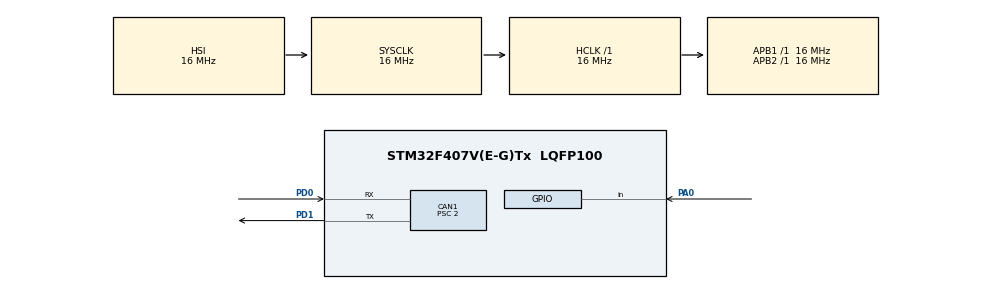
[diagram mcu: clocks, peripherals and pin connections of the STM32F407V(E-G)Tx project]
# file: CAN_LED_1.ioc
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CAN1.BS1=CAN_BS1_13TQ
CAN1.BS2=CAN_BS2_2TQ
CAN1.CalculateBaudRate=500000
CAN1.CalculateTimeBit=2000
CAN1.CalculateTimeQuantum=125.0
CAN1.NART=ENABLE
CAN1.Prescaler=2
Mcu.Family=STM32F4
Mcu.Name=STM32F407V(E-G)Tx
Mcu.Package=LQFP100
NVIC.PriorityGroup=NVIC_PRIORITYGROUP_4
PA0-WKUP.Signal=GPIO_Input
PD0.Mode=CAN_Activate
PD0.Signal=CAN1_RX
PD1.Mode=CAN_Activate
PD1.Signal=CAN1_TX
ProjectManager.HeapSize=0x200
ProjectManager.StackSize=0x400
ProjectManager.TargetToolchain=STM32CubeIDE
RCC.AHBFreq_Value=16000000
RCC.APB1Freq_Value=16000000
RCC.APB2Freq_Value=16000000
RCC.CortexFreq_Value=16000000
RCC.HSE_VALUE=25000000
RCC.HSI_VALUE=16000000
RCC.LSE_VALUE=32768
RCC.SYSCLKFreq_VALUE=16000000
RCC.VCOOutputFreq_Value=192000000
board=custom

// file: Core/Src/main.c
/* USER CODE BEGIN Header */
/**
  ******************************************************************************
  * @file           : main.c
  * @brief          : Main program body
  ******************************************************************************
  * @attention
  *
  * Copyright (c) 2026 STMicroelectronics.
  * All rights reserved.
  *
  * This software is licensed under terms that can be found in the LICENSE file
  * in the root directory of this software component.
  * If no LICENSE file comes with this software, it is provided AS-IS.
  *
  ******************************************************************************
  */
/* USER CODE END Header */
#include "main.h"

CAN_HandleTypeDef hcan1;

/* USER CODE BEGIN PV */
CAN_TxHeaderTypeDef TxHeader;
uint8_t TxData[1];
uint32_t TxMailbox;

uint8_t buttonLastState = 0;
uint32_t lastDebounceTime = 0;
#define DEBOUNCE_MS 50
/* USER CODE END PV */

void SystemClock_Config(void);
static void MX_GPIO_Init(void);
static void MX_CAN1_Init(void);

int main(void)
{

  /* MCU Configuration--------------------------------------------------------*/

  /* Reset of all peripherals, Initializes the Flash interface and the Systick. */
  HAL_Init();

  /* Configure the system clock */
  SystemClock_Config();

  /* Initialize all configured peripherals */
  MX_GPIO_Init();
  MX_CAN1_Init();
  /* USER CODE BEGIN 2 */
  CAN_FilterTypeDef canFilter;
  canFilter.FilterBank = 0;
  canFilter.FilterMode = CAN_FILTERMODE_IDMASK;
  canFilter.FilterScale = CAN_FILTERSCALE_32BIT;
  canFilter.FilterIdHigh = 0x0000;
  canFilter.FilterIdLow = 0x0000;
  canFilter.FilterMaskIdHigh = 0x0000;
  canFilter.FilterMaskIdLow = 0x0000;
  canFilter.FilterFIFOAssignment = CAN_FILTER_FIFO0;
  canFilter.FilterActivation = ENABLE;
  canFilter.SlaveStartFilterBank = 14;

  if (HAL_CAN_ConfigFilter(&hcan1, &canFilter) != HAL_OK)
  {
    Error_Handler();
  }

  if (HAL_CAN_Start(&hcan1) != HAL_OK)
  {
    Error_Handler();
  }

  TxHeader.StdId = 0x100;
  TxHeader.ExtId = 0;
  TxHeader.IDE = CAN_ID_STD;
  TxHeader.RTR = CAN_RTR_DATA;
  TxHeader.DLC = 1;
  TxHeader.TransmitGlobalTime = DISABLE;
  /* USER CODE END 2 */

  /* Infinite loop */
  /* USER CODE BEGIN WHILE */
  while (1)
  {
	  uint8_t buttonState = HAL_GPIO_ReadPin(GPIOA, GPIO_PIN_0);

	  // Rising-edge detect with simple software debounce
	  if (buttonState == GPIO_PIN_SET && buttonLastState == GPIO_PIN_RESET
	      && (HAL_GetTick() - lastDebounceTime) > DEBOUNCE_MS)
	  {
	    TxData[0] = 0xAA;

	    if (HAL_CAN_AddTxMessage(&hcan1, &TxHeader, TxData, &TxMailbox) != HAL_OK)
	    {
	      Error_Handler();
	    }

	    lastDebounceTime = HAL_GetTick();
	  }

	  buttonLastState = buttonState;
    /* USER CODE END WHILE */

  }
}

void SystemClock_Config(void)
{
  RCC_OscInitTypeDef RCC_OscInitStruct = {0};
  RCC_ClkInitTypeDef RCC_ClkInitStruct = {0};

  /** Configure the main internal regulator output voltage
  */
  __HAL_RCC_PWR_CLK_ENABLE();
  __HAL_PWR_VOLTAGESCALING_CONFIG(PWR_REGULATOR_VOLTAGE_SCALE1);

  /** Initializes the RCC Oscillators according to the specified parameters
  * in the RCC_OscInitTypeDef structure.
  */
  RCC_OscInitStruct.OscillatorType = RCC_OSCILLATORTYPE_HSI;
  RCC_OscInitStruct.HSIState = RCC_HSI_ON;
  RCC_OscInitStruct.HSICalibrationValue = RCC_HSICALIBRATION_DEFAULT;
  RCC_OscInitStruct.PLL.PLLState = RCC_PLL_NONE;
  if (HAL_RCC_OscConfig(&RCC_OscInitStruct) != HAL_OK)
  {
    Error_Handler();
  }

  /** Initializes the CPU, AHB and APB buses clocks
  */
  RCC_ClkInitStruct.ClockType = RCC_CLOCKTYPE_HCLK|RCC_CLOCKTYPE_SYSCLK
                              |RCC_CLOCKTYPE_PCLK1|RCC_CLOCKTYPE_PCLK2;
  RCC_ClkInitStruct.SYSCLKSource = RCC_SYSCLKSOURCE_HSI;
  RCC_ClkInitStruct.AHBCLKDivider = RCC_SYSCLK_DIV1;
  RCC_ClkInitStruct.APB1CLKDivider = RCC_HCLK_DIV1;
  RCC_ClkInitStruct.APB2CLKDivider = RCC_HCLK_DIV1;

  if (HAL_RCC_ClockConfig(&RCC_ClkInitStruct, FLASH_LATENCY_0) != HAL_OK)
  {
    Error_Handler();
  }
}

static void MX_CAN1_Init(void)
{

  hcan1.Instance = CAN1;
  hcan1.Init.Prescaler = 2;
  hcan1.Init.Mode = CAN_MODE_NORMAL;
  hcan1.Init.SyncJumpWidth = CAN_SJW_1TQ;
  hcan1.Init.TimeSeg1 = CAN_BS1_13TQ;
  hcan1.Init.TimeSeg2 = CAN_BS2_2TQ;
  hcan1.Init.TimeTriggeredMode = DISABLE;
  hcan1.Init.AutoBusOff = DISABLE;
  hcan1.Init.AutoWakeUp = DISABLE;
  hcan1.Init.AutoRetransmission = ENABLE;
  hcan1.Init.ReceiveFifoLocked = DISABLE;
  hcan1.Init.TransmitFifoPriority = DISABLE;
  if (HAL_CAN_Init(&hcan1) != HAL_OK)
  {
    Error_Handler();
  }

}

static void MX_GPIO_Init(void)
{
  GPIO_InitTypeDef GPIO_InitStruct = {0};

  /* GPIO Ports Clock Enable */
  __HAL_RCC_GPIOA_CLK_ENABLE();
  __HAL_RCC_GPIOD_CLK_ENABLE();

  /*Configure GPIO pin : PA0 */
  GPIO_InitStruct.Pin = GPIO_PIN_0;
  GPIO_InitStruct.Mode = GPIO_MODE_INPUT;
  GPIO_InitStruct.Pull = GPIO_NOPULL;
  HAL_GPIO_Init(GPIOA, &GPIO_InitStruct);

}

void Error_Handler(void)
{
  __disable_irq();
  while (1)
  {
  }
}
